# D1H register map
Vendor: Allwinner; File version: 1.0
Registers are 32-bit, read-write, reset 0x0 unless marked. A register's access mark holds for its fields unless they carry their own. Offsets are from the block's base; [hi:lo] are bit positions; {n}, {i} and the like mark numbered series.

## USB1 — USB2.0 HOST
Base 0x04200000
0x00 E_CAPLENGTH — EHCI Capability Register Length Register
0x02 E_HCIVERSION — EHCI Host Interface Version Number Register
0x04 E_HCSPARAMS — EHCI Host Control Structural Parameter Register
0x08 E_HCCPARAMS — EHCI Host Control Capability Parameter Register
0x0C E_HCSPPORTROUTE — EHCI Companion Port Route Description
0x10 E_USBCMD — EHCI USB Command Register
0x14 E_USBSTS — EHCI USB Status Register
0x18 E_USBINTR — EHCI USB Interrupt Enable Register
0x1C E_FRINDEX — EHCI USB Frame Index Register
0x20 E_CTRLDSSEGMENT — EHCI 4G Segment Selector Register
0x24 E_PERIODICLISTBASE — EHCI Frame List Base Address Register
0x28 E_ASYNCLISTADDR — EHCI Next Asynchronous List Address Register
0x50 E_CONFIGFLAG — EHCI Configured Flag Register
0x54 E_PORTSC — EHCI Port Status/Control Register
0x404 O_HcControl — OHCI Control Register
0x408 O_HcCommandStatus — OHCI Command Status Register
0x40C O_HcInterruptStatus — OHCI Interrupt Status Register
0x410 O_HcInterruptEnable — OHCI Interrupt Enable Register
0x414 O_HcInterruptDisable — OHCI Interrupt Disable Register
0x418 O_HcHCCA — OHCI HCCA Base
0x41C O_HcPeriodCurrentED — OHCI Period Current ED Base
0x420 O_HcControlHeadED — OHCI Control Head ED Base
0x424 O_HcControlCurrentED — OHCI Control Current ED Base
0x428 O_HcBulkHeadED — OHCI Bulk Head ED Base
0x42C O_HcBulkCurrentED — OHCI Bulk Current ED Base
0x430 O_HcDoneHead — OHCI Done Head Base
0x434 O_HcFmInterval — OHCI Frame Interval Register
0x438 O_HcFmRemaining — OHCI Frame Remaining Register
0x43C O_HcFmNumber — OHCI Frame Number Register
0x440 O_HcPerioddicStart — OHCI Periodic Start Register
0x444 O_HcLSThreshold — OHCI LS Threshold Register
0x448 O_HcRhDescriptorA — OHCI Root Hub Descriptor Register A
0x44C O_HcRhDesriptorB — OHCI Root Hub Descriptor Register B
0x450 O_HcRhStatus — OHCI Root Hub Status Register
0x454 O_HcRhPortStatus — OHCI Root Hub Port Status Register
0x800 HCI_Interface
0x808 HCI_CTRL3 — HCI Control Register
0x810 PHY_Control
0x824 PHY_STATUS
0x828 HCI_SIE_PORT_DISABLE_CONTROL

## GPADC — General Purpose ADC
Base 0x02009000
0x00 GP_SR_CON — GPADC Sample Rate Configure Register
0x04 GP_CTRL — GPADC Control Register
0x08 GP_CS_EN — GPADC Compare and Select Enable Register
0x0C GP_FIFO_INTC — GPADC FIFO Interrupt Control Register
0x10 GP_FIFO_INTS — GPADC FIFO Interrupt Status Register
0x14 GP_FIFO_DATA — GPADC FIFO Data Register
0x18 GP_CDATA — GPADC Calibration Data Register
0x20 GP_DATAL_INTC — GPADC Data Low Interrupt Configure Register
0x24 GP_DATAH_INTC — GPADC Data High Interrupt Configure Register
0x28 GP_DATA_INTC — GPADC Data Interrupt Configure Register
0x30 GP_DATAL_INTS — GPADC Data Low Interrupt Status Register
0x34 GP_DATAH_INTS — GPADC Data High Interrupt Status Register
0x38 GP_DATA_INTS — GPADC Data Interrupt Status Register
0x40 GP_CH0_CMP_DATA — GPADC CH0 Compare Data Register
0x44 GP_CH1_CMP_DATA — GPADC CH1 Compare Data Register
0x80 GP_CH0_DATA — GPADC CH0 Data Register
0x84 GP_CH1_DATA — GPADC CH1 Data Register

## TPADC — Touch Panel ADC
Base 0x02009C00
{0x0+4i} TP_CTRL{i} (i=0..3) — TP Control Register {i}
0x10 TP_INT_FIFO_CTRL — TP Interrupt FIFO Control Register
0x14 TP_INT_FIFO_STAT — TP Interrupt FIFO Status Register
0x1C TP_CALI_DATA — TP Calibration Data Register
0x24 TP_DATA

## LRADC — Low Rate ADC
Base 0x02009800
0x00 LRADC_CTRL — LRADC Control Register
0x04 LRADC_INTC — LRADC Interrupt Control Register
0x08 LRADC_INTS — LRADC Interrupt Status Register
0x0C LRADC_DATA

## PWM — Pulse Width Modulation
Base 0x02000C00
0x00 PIER — PWM IRQ Enable Register
0x04 PISR — PWM IRQ Status Register
0x10 CIER — Capture IRQ Enable Register
0x14 CISR — Capture IRQ Status Register
0x20 PCCR01 — PWM01 Clock Configuration Register
0x24 PCCR23 — PWM23 Clock Configuration Register
0x28 PCCR45 — PWM45 Clock Configuration Register
0x2C PCCR67 — PWM67 Clock Configuration Register
0x40 PCGR — PWM Clock Gating Register
0x60 PDZCR01 — PWM01 Dead Zone Control Register
0x64 PDZCR23 — PWM23 Dead Zone Control Register
0x68 PDZCR45 — PWM45 Dead Zone Control Register
0x6C PDZCR67 — PWM67 Dead Zone Control Register
0x80 PER — PWM Enable Register
{0x90+4i} PGR{i} (i=0..3) — PWM Group{i} Register
0xC0 CER — Capture Enable Register
{0x100+0x20*i} pcr{i} (i=0..7) — PWM Control Register
{0x104+0x20*i} ppr{i} (i=0..7) — PWM Period Register
{0x108+0x20*i} pcntr{i} (i=0..7) — PWM Count Register
{0x10C+0x20*i} ppcntr{i} (i=0..7) — PWM Pulse Count Register
{0x110+0x20*i} ccr{i} (i=0..7) — Capture Control Register
{0x114+0x20*i} crlr{i} (i=0..7) — Capture Rise Lock Register
{0x118+0x20*i} cflr{i} (i=0..7) — Capture Fall Lock Register

## LEDC
Base 0x02008000
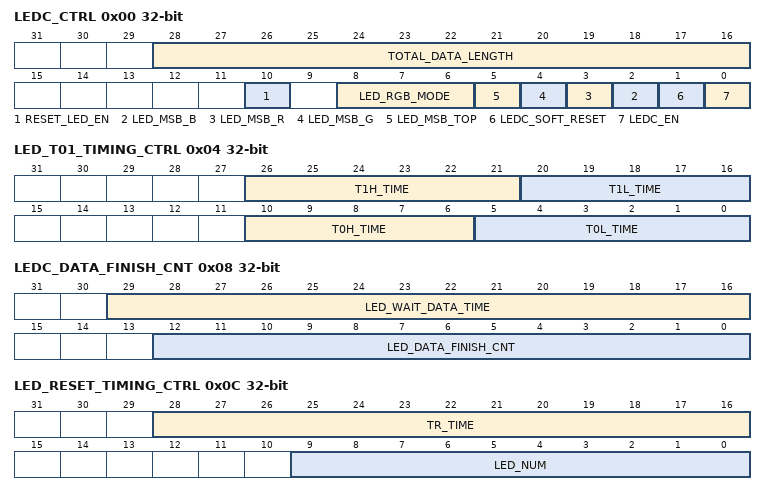
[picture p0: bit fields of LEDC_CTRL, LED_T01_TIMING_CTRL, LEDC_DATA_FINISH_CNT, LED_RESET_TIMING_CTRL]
0x00 LEDC_CTRL — LEDC Control Register
  [28:16] TOTAL_DATA_LENGTH
  [10] RESET_LED_EN
  [8:6] LED_RGB_MODE
    0=GRB; 1=GBR; 2=RGB; 3=RBG; 4=BGR; 5=BRG
  [2] LED_MSB_{x} (x=B,R,G,TOP; step 1)
    0=LSB; 1=MSB
  [1] LEDC_SOFT_RESET
  [0] LEDC_EN
    0=Disable; 1=Enable
0x04 LED_T01_TIMING_CTRL — LEDC T0 T1 Timing Control Register
  [26:21] T1H_TIME range 0..0x3f, [20:16] T1L_TIME range 0..0x1f, [10:6] T0H_TIME range 0..0x1f, [5:0] T0L_TIME range 0..0x1f
0x08 LEDC_DATA_FINISH_CNT — LEDC Data Finish Counter Register
  [29:16] LED_WAIT_DATA_TIME range 0..0x1FFF, [12:0] LED_DATA_FINISH_CNT ro
0x0C LED_RESET_TIMING_CTRL — LEDC Reset Timing Control Register
  [28:16] TR_TIME range 1..0x1FFF, [9:0] LED_NUM
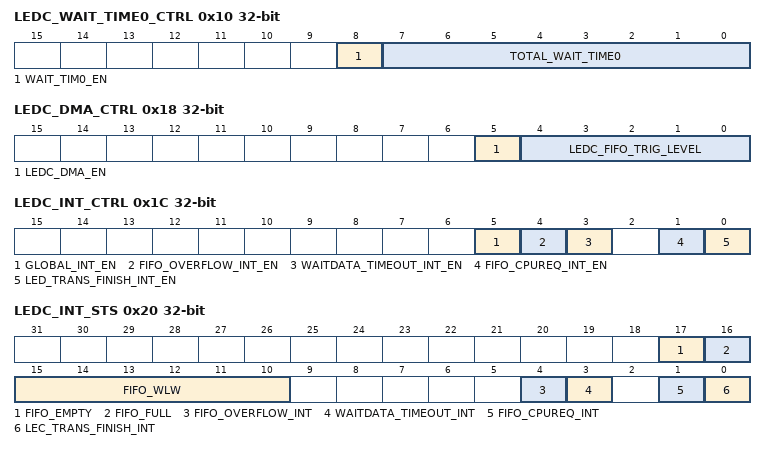
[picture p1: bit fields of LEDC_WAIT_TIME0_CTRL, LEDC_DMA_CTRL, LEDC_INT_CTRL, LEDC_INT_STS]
0x10 LEDC_WAIT_TIME0_CTRL — LEDC Wait Time0 Control Register
  [8] WAIT_TIM0_EN
    0=Disable; 1=Enable
  [7:0] TOTAL_WAIT_TIME0 range 1..0xFF
0x14 LEDC_DATA wo
0x18 LEDC_DMA_CTRL — LEDC DMA Control Register
  [5] LEDC_DMA_EN
    0=Disable; 1=Enable
  [4:0] LEDC_FIFO_TRIG_LEVEL
0x1C LEDC_INT_CTRL — LEDC Interrupt Control Register
  [all] fields
    0=Disable; 1=Enable
  [5] GLOBAL_INT_EN
  [4] FIFO_OVERFLOW_INT_EN
  [3] WAITDATA_TIMEOUT_INT_EN
  [1] FIFO_CPUREQ_INT_EN
  [0] LED_TRANS_FINISH_INT_EN
0x20 LEDC_INT_STS — LEDC Interrupt Status Register
  [17] FIFO_EMPTY ro
  [16] FIFO_FULL ro
  [15:10] FIFO_WLW ro
  [4] FIFO_OVERFLOW_INT write-1-clears
    0=not_overflow; 1=overflow
  [3] WAITDATA_TIMEOUT_INT write-1-clears
    0=not_timeout; 1=timeout
  [1] FIFO_CPUREQ_INT write-1-clears
    0=not_request; 1=request
  [0] LEC_TRANS_FINISH_INT write-1-clears
    0=not_trans_complete; 1=trans_complete
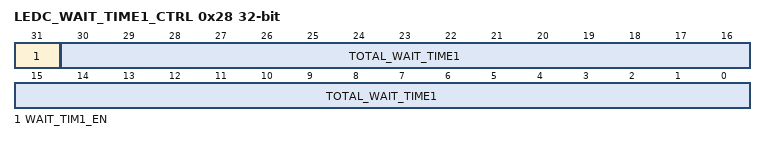
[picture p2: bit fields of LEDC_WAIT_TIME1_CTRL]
0x28 LEDC_WAIT_TIME1_CTRL — LEDC Wait Time1 Control Register
  [31] WAIT_TIM1_EN
    0=Disable; 1=Enable
  [30:0] TOTAL_WAIT_TIME1 range 0x80..0x7FFFFFFF
{0x30+4i} LEDC_FIFO_DATA{i} (i=0..31) ro

## CIR_RX — Counsumer Infrared Receiver
Base 0x07040000
0x00 CIR_CTL — CIR Control Register
0x10 CIR_RXPCFG — CIR Receiver Pulse Configure Register
0x20 CIR_RXFIFO — CIR Receiver FIFO Register
0x2C CIR_RXINT — CIR Receiver Interrupt Control Register
0x30 CIR_RXSTA — CIR Receiver Status Register
0x34 CIR_RXCFG — CIR Receiver Configure Register

## CIR_TX — Counsumer Infrared Transmitter
Base 0x02003000
0x00 CIR_TGLR — CIR Transmit Global Register
0x04 CIR_TMCR — CIR Transmit Modulation Control Register
0x08 CIR_TCR — CIR Transmit Control Register
0x0C CIR_IDC_H — CIR Transmit Idle Duration Threshold High Bit Register
0x10 CIR_IDC_L — CIR Transmit Idle Duration Threshold Low Bit Register
0x14 CIR_TICR_H — CIR Transmit Idle Counter High Bit Register
0x18 CIR_TICR_L — CIR Transmit Idle Counter Low Bit Register
0x20 CIR_TEL — CIR TX FIFO Empty Level Register
0x24 CIR_TXINT — CIR Transmit Interrupt Control Register
0x28 CIR_TAC — CIR Transmit FIFO Available Counter Register
0x2C CIR_TXSTA — CIR Transmit Status Register
0x30 CIR_TXT — CIR Transmit Threshold Register
0x34 CIR_DMA — CIR DMA Control Register
0x80 CIR_TXFIFO — CIR Transmit FIFO Data Register

## CE_NS — Crypoto Engine
Base 0x03040000
0x00 CE_TDA — Task Descriptor Address
0x08 CE_ICR — Interrupt Control Register
0x0C CE_ISR — Interrupt Status Register
0x10 CE_TLR — Task Load Register
0x14 CE_TSR — Task Status Register
0x18 CE_ESR — Error Status Register
0x24 CE_CSA — DMA Current Source Address
0x28 CE_CDA — DMA Current Destination Address
0x2C CE_TPR — Throughput Register
